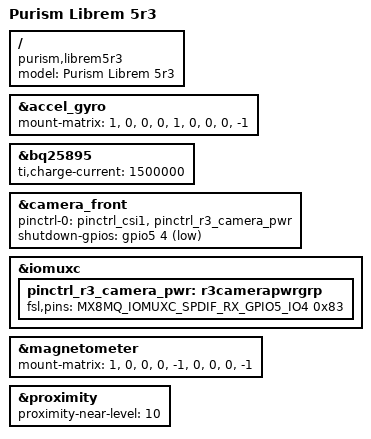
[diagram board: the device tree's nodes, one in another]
/dts-v1/;
#include "imx8mq-librem5.dtsi"
/ {
	model = "Purism Librem 5r3";
	compatible = "purism,librem5r3", "purism,librem5", "fsl,imx8mq";
};
&accel_gyro {
	mount-matrix = "1",  "0",  "0",
		       "0",  "1",  "0",
		       "0",  "0", "-1";
};
&bq25895 {
	ti,charge-current = <1500000>;  
};
&camera_front {
	pinctrl-0 = <&pinctrl_csi1>, <&pinctrl_r3_camera_pwr>;
	shutdown-gpios = <&gpio5 4 GPIO_ACTIVE_LOW>;
};
&iomuxc {
	pinctrl_r3_camera_pwr: r3camerapwrgrp {
		fsl,pins = <
			MX8MQ_IOMUXC_SPDIF_RX_GPIO5_IO4		0x83
		>;
	};
};
&magnetometer {
	mount-matrix = "1",  "0",  "0",
		       "0", "-1",  "0",
		       "0",  "0", "-1";
};
&proximity {
	proximity-near-level = <10>;
};
